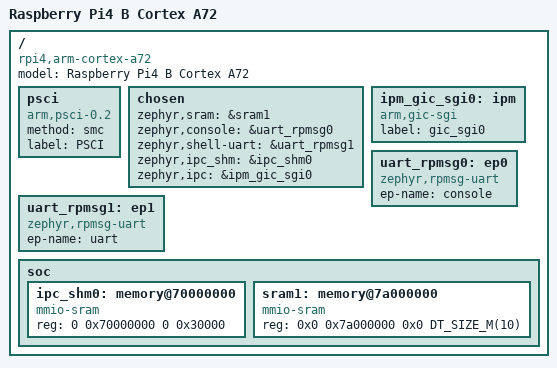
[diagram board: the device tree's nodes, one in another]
/*
 * Copyright (c) 2022 openEuler Embedded
 *
 * SPDX-License-Identifier: Apache-2.0
 *
 */

/dts-v1/;
#include <arm64/broadcom/rpi4-a72.dtsi>

/ {
	model = "Raspberry Pi4 B Cortex A72";
	compatible = "rpi4,arm-cortex-a72";

	psci {
		compatible = "arm,psci-0.2";
		method = "smc";
		label = "PSCI";
	};

	chosen {
		zephyr,sram = &sram1;
		zephyr,console = &uart_rpmsg0;
		zephyr,shell-uart = &uart_rpmsg1;
		/*
		 * shared memory reserved for the inter-processor communication
		 */
		 zephyr,ipc_shm = &ipc_shm0;
		 zephyr,ipc = &ipm_gic_sgi0;
	};

	ipm_gic_sgi0: ipm{
		compatible = "arm,gic-sgi";
		label = "gic_sgi0";
	};

	uart_rpmsg0: ep0 {
		status = "okay";
		compatible = "zephyr,rpmsg-uart";
		ep-name = "console";
	};

	uart_rpmsg1: ep1 {
		status = "okay";
		compatible = "zephyr,rpmsg-uart";
		ep-name = "uart";
	};

	soc {

		ipc_shm0: memory@70000000 {
			compatible = "mmio-sram";
			reg = <0 0x70000000 0 0x30000>;
		};

		sram1: memory@7a000000 {
			compatible = "mmio-sram";
			reg = <0x0 0x7a000000 0x0 DT_SIZE_M(10)>;
		};

	};
};
